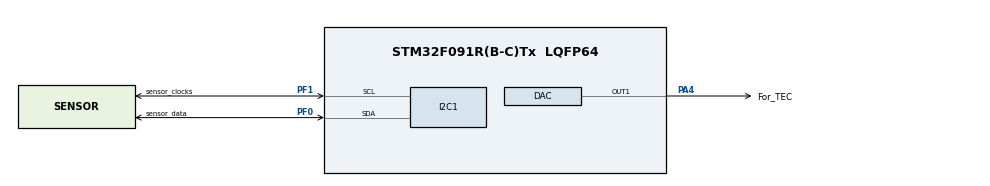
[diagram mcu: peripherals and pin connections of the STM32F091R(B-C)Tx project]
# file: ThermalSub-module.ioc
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DAC.DAC_Trigger=DAC_TRIGGER_T6_TRGO
Dma.DAC_CH1.1.Direction=DMA_MEMORY_TO_PERIPH
Dma.DAC_CH1.1.Instance=DMA2_Channel3
Dma.DAC_CH1.1.MemDataAlignment=DMA_MDATAALIGN_HALFWORD
Dma.DAC_CH1.1.MemInc=DMA_MINC_ENABLE
Dma.DAC_CH1.1.Mode=DMA_CIRCULAR
Dma.DAC_CH1.1.PeriphDataAlignment=DMA_PDATAALIGN_HALFWORD
Dma.DAC_CH1.1.PeriphInc=DMA_PINC_DISABLE
Dma.DAC_CH1.1.Priority=DMA_PRIORITY_LOW
Dma.I2C1_RX.0.Direction=DMA_PERIPH_TO_MEMORY
Dma.I2C1_RX.0.Instance=DMA1_Channel3
Dma.I2C1_RX.0.MemDataAlignment=DMA_MDATAALIGN_BYTE
Dma.I2C1_RX.0.MemInc=DMA_MINC_ENABLE
Dma.I2C1_RX.0.Mode=DMA_CIRCULAR
Dma.I2C1_RX.0.PeriphDataAlignment=DMA_PDATAALIGN_BYTE
Dma.I2C1_RX.0.PeriphInc=DMA_PINC_DISABLE
Dma.I2C1_RX.0.Priority=DMA_PRIORITY_LOW
Dma.Request0=I2C1_RX
Dma.Request1=DAC_CH1
I2C1.AddressingMode=I2C_ADDRESSINGMODE_7BIT
I2C1.DualAddressMode=I2C_DUALADDRESS_DISABLE
I2C1.GeneralCallMode=I2C_GENERALCALL_ENABLE
Mcu.Family=STM32F0
Mcu.Name=STM32F091R(B-C)Tx
Mcu.Package=LQFP64
NVIC.DMA1_Ch2_3_DMA2_Ch1_2_IRQn=true\:0\:0\:false\:false\:true\:false\:true\:true
NVIC.DMA1_Ch4_7_DMA2_Ch3_5_IRQn=true\:0\:0\:false\:false\:true\:false\:true\:true
NVIC.I2C1_IRQn=true\:0\:0\:false\:false\:true\:true\:true\:true
PA4.GPIO_Label=For_TEC
PA4.Signal=COMP_DAC1_group
PF0-OSC_IN.GPIO_Label=sensor_data
PF0-OSC_IN.GPIO_Pu=GPIO_PULLUP
PF0-OSC_IN.Mode=I2C
PF0-OSC_IN.Signal=I2C1_SDA
PF1-OSC_OUT.GPIO_Label=sensor_clocks
PF1-OSC_OUT.GPIO_Pu=GPIO_PULLUP
PF1-OSC_OUT.Mode=I2C
PF1-OSC_OUT.Signal=I2C1_SCL
ProjectManager.HeapSize=0x200
ProjectManager.StackSize=0x400
ProjectManager.TargetToolchain=STM32CubeIDE
SH.COMP_DAC1_group.0=DAC_OUT1,DAC_OUT1
TIM6.Period=10000 - 1
TIM6.Prescaler=64-1
TIM6.TIM_MasterOutputTrigger=TIM_TRGO_UPDATE
VP_TIM6_VS_ClockSourceINT.Mode=Enable_Timer
board=custom

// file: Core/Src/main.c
/* USER CODE BEGIN Header */
/**
  ******************************************************************************
  * @file           : main.c
  * @brief          : Main program body
  ******************************************************************************
  * @attention
  *
  * Copyright (c) 2024 STMicroelectronics.
  * All rights reserved.
  *
  * This software is licensed under terms that can be found in the LICENSE file
  * in the root directory of this software component.
  * If no LICENSE file comes with this software, it is provided AS-IS.
  *
  ******************************************************************************
  */
/* USER CODE END Header */
#include "main.h"

DAC_HandleTypeDef hdac;
DMA_HandleTypeDef hdma_dac_ch1;

I2C_HandleTypeDef hi2c1;
DMA_HandleTypeDef hdma_i2c1_rx;

TIM_HandleTypeDef htim6;

/* USER CODE BEGIN PV */
uint32_t Vout;

/* USER CODE END PV */

void SystemClock_Config(void);
static void MX_GPIO_Init(void);
static void MX_DMA_Init(void);
static void MX_DAC_Init(void);
static void MX_I2C1_Init(void);
static void MX_TIM6_Init(void);
static void Thermal(void);
static void set_Vout(float u_t);
float get_sensor_data(void);

float desired_temp = 27;
int main(void)
{

  /* MCU Configuration--------------------------------------------------------*/

  /* Reset of all peripherals, Initializes the Flash interface and the Systick. */
  HAL_Init();

  /* Configure the system clock */
  SystemClock_Config();

  /* Initialize all configured peripherals */
  MX_GPIO_Init();
  MX_DMA_Init();
  MX_DAC_Init();
  MX_I2C1_Init();
  MX_TIM6_Init();
  /* USER CODE BEGIN 2 */
  HAL_TIM_Base_Start(&htim6);
  HAL_DAC_Start_DMA(&hdac, DAC_CHANNEL_1, &Vout, 1, DAC_ALIGN_8B_R);
  Thermal();
  /* USER CODE END 2 */

  /* Infinite loop */
  while (1)
  {

  }
}
void Thermal(void){
    volatile float r_t = desired_temp;
    float y_t, u_t, diff, P, I;
    float MAX_LIMIT = 10;
    float MIN_LIMIT = -10;
	float K_p = 2;
    float K_i = 0.5;
    float diff_sum = 0;
    float last_diff = 0;

    while (1){
        y_t = get_sensor_data();
        diff = r_t - y_t;
        diff_sum = diff + last_diff;
        P = P + K_p * diff;
        I = K_i * diff_sum;
        if(I > MAX_LIMIT) I = MAX_LIMIT;
        else if(I < MIN_LIMIT) I = MIN_LIMIT;
        u_t = P + I;
        if(u_t > MAX_LIMIT) u_t = MAX_LIMIT;
        else if(u_t < MIN_LIMIT) u_t = MIN_LIMIT;
        set_Vout(u_t);
    }; //loops until process is killed by the controller

    return;
}

float get_sensor_data(void){
	double temp = 0;
	uint8_t buf[8][2];
	float temp_vals[8];
	int temp_hold;
	for(uint8_t i = 0x48; i < 0x50; i += 1){
		buf[i][1] = 0x00;
		if(HAL_I2C_Master_Transmit(&hi2c1, i, buf[i], 1, 5000) == HAL_OK ){
			HAL_I2C_Master_Receive(&hi2c1, i, buf[i], 2, 5000);
		}
		temp_hold = (int) buf[i][0];
		temp_hold <<= 4;
		temp_vals[i] = (float) (temp_hold | (buf[i][1] & 0xF0));
		temp_vals[i] = temp_vals[i] > 0 ? temp_vals[i] / 16: (temp_vals[i] - 4096) / 16;
		temp += temp_vals[i];
	}
	return (temp / 8);
}

void set_Vout(float u_t){
	Vout = (int) u_t;
	return;
}

void SystemClock_Config(void)
{
  RCC_OscInitTypeDef RCC_OscInitStruct = {0};
  RCC_ClkInitTypeDef RCC_ClkInitStruct = {0};
  RCC_PeriphCLKInitTypeDef PeriphClkInit = {0};

  /** Initializes the RCC Oscillators according to the specified parameters
  * in the RCC_OscInitTypeDef structure.
  */
  RCC_OscInitStruct.OscillatorType = RCC_OSCILLATORTYPE_HSI;
  RCC_OscInitStruct.HSIState = RCC_HSI_ON;
  RCC_OscInitStruct.HSICalibrationValue = RCC_HSICALIBRATION_DEFAULT;
  RCC_OscInitStruct.PLL.PLLState = RCC_PLL_NONE;
  if (HAL_RCC_OscConfig(&RCC_OscInitStruct) != HAL_OK)
  {
    Error_Handler();
  }

  /** Initializes the CPU, AHB and APB buses clocks
  */
  RCC_ClkInitStruct.ClockType = RCC_CLOCKTYPE_HCLK|RCC_CLOCKTYPE_SYSCLK
                              |RCC_CLOCKTYPE_PCLK1;
  RCC_ClkInitStruct.SYSCLKSource = RCC_SYSCLKSOURCE_HSI;
  RCC_ClkInitStruct.AHBCLKDivider = RCC_SYSCLK_DIV1;
  RCC_ClkInitStruct.APB1CLKDivider = RCC_HCLK_DIV1;

  if (HAL_RCC_ClockConfig(&RCC_ClkInitStruct, FLASH_LATENCY_0) != HAL_OK)
  {
    Error_Handler();
  }
  PeriphClkInit.PeriphClockSelection = RCC_PERIPHCLK_I2C1;
  PeriphClkInit.I2c1ClockSelection = RCC_I2C1CLKSOURCE_HSI;
  if (HAL_RCCEx_PeriphCLKConfig(&PeriphClkInit) != HAL_OK)
  {
    Error_Handler();
  }
}

static void MX_DAC_Init(void)
{

  DAC_ChannelConfTypeDef sConfig = {0};

  /** DAC Initialization
  */
  hdac.Instance = DAC;
  if (HAL_DAC_Init(&hdac) != HAL_OK)
  {
    Error_Handler();
  }

  /** DAC channel OUT1 config
  */
  sConfig.DAC_Trigger = DAC_TRIGGER_T6_TRGO;
  sConfig.DAC_OutputBuffer = DAC_OUTPUTBUFFER_ENABLE;
  if (HAL_DAC_ConfigChannel(&hdac, &sConfig, DAC_CHANNEL_1) != HAL_OK)
  {
    Error_Handler();
  }

}

static void MX_I2C1_Init(void)
{

  hi2c1.Instance = I2C1;
  hi2c1.Init.Timing = 0x2000090E;
  hi2c1.Init.OwnAddress1 = 0;
  hi2c1.Init.AddressingMode = I2C_ADDRESSINGMODE_7BIT;
  hi2c1.Init.DualAddressMode = I2C_DUALADDRESS_DISABLE;
  hi2c1.Init.OwnAddress2 = 0;
  hi2c1.Init.OwnAddress2Masks = I2C_OA2_NOMASK;
  hi2c1.Init.GeneralCallMode = I2C_GENERALCALL_ENABLE;
  hi2c1.Init.NoStretchMode = I2C_NOSTRETCH_DISABLE;
  if (HAL_I2C_Init(&hi2c1) != HAL_OK)
  {
    Error_Handler();
  }

  /** Configure Analogue filter
  */
  if (HAL_I2CEx_ConfigAnalogFilter(&hi2c1, I2C_ANALOGFILTER_ENABLE) != HAL_OK)
  {
    Error_Handler();
  }

  /** Configure Digital filter
  */
  if (HAL_I2CEx_ConfigDigitalFilter(&hi2c1, 0) != HAL_OK)
  {
    Error_Handler();
  }

}

static void MX_TIM6_Init(void)
{

  TIM_MasterConfigTypeDef sMasterConfig = {0};

  htim6.Instance = TIM6;
  htim6.Init.Prescaler = 64-1;
  htim6.Init.CounterMode = TIM_COUNTERMODE_UP;
  htim6.Init.Period = 10000 - 1;
  htim6.Init.AutoReloadPreload = TIM_AUTORELOAD_PRELOAD_DISABLE;
  if (HAL_TIM_Base_Init(&htim6) != HAL_OK)
  {
    Error_Handler();
  }
  sMasterConfig.MasterOutputTrigger = TIM_TRGO_UPDATE;
  sMasterConfig.MasterSlaveMode = TIM_MASTERSLAVEMODE_DISABLE;
  if (HAL_TIMEx_MasterConfigSynchronization(&htim6, &sMasterConfig) != HAL_OK)
  {
    Error_Handler();
  }

}

static void MX_DMA_Init(void)
{

  /* DMA controller clock enable */
  __HAL_RCC_DMA1_CLK_ENABLE();
  __HAL_RCC_DMA2_CLK_ENABLE();

  /* DMA interrupt init */
  /* DMA1_Ch2_3_DMA2_Ch1_2_IRQn interrupt configuration */
  HAL_NVIC_SetPriority(DMA1_Ch2_3_DMA2_Ch1_2_IRQn, 0, 0);
  HAL_NVIC_EnableIRQ(DMA1_Ch2_3_DMA2_Ch1_2_IRQn);
  /* DMA1_Ch4_7_DMA2_Ch3_5_IRQn interrupt configuration */
  HAL_NVIC_SetPriority(DMA1_Ch4_7_DMA2_Ch3_5_IRQn, 0, 0);
  HAL_NVIC_EnableIRQ(DMA1_Ch4_7_DMA2_Ch3_5_IRQn);

}

static void MX_GPIO_Init(void)
{

  /* GPIO Ports Clock Enable */
  __HAL_RCC_GPIOF_CLK_ENABLE();
  __HAL_RCC_GPIOA_CLK_ENABLE();

}

void Error_Handler(void)
{
  __disable_irq();
  while (1)
  {
  }
}
